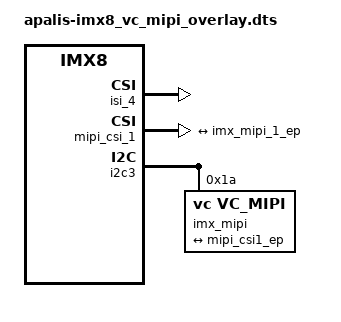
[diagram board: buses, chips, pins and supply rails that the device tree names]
/dts-v1/;
/plugin/;

#include <dt-bindings/clock/imx8-clock.h>
#include <dt-bindings/gpio/gpio.h>

// ------------------------------------------------------------------------------------------------
//  Supported number of lanes
// -----+------------------------------------------------------------------------------------------
//  1   | IMX296
//  2   | OV9281, IMX264, IMX265
//  2,4 | IMX178, IMX183, IMX226, IMX250, IMX252, IMX273, IMX290, IMX327, IMX392, IMX412, IMX415
// -----+------------------------------------------------------------------------------------------
#define VC_MIPI_LANES   2

#if VC_MIPI_LANES == 1
    #define DATA_LANES <1>
    #define NUM_LANES "1" 
#endif
#if VC_MIPI_LANES == 2
    #define DATA_LANES <1 2>
    #define NUM_LANES "2" 
#endif

/ {
	compatible = "toradex,apalis-imx8";
};

&isi_4 { 
	status = "okay";

	cap_device {
		status = "okay";
	};
};

&mipi_csi_1 { 
	#address-cells = <1>;
	#size-cells = <0>;
	// /delete-property/virtual-channel;
	status = "okay";

	port@1 {
		reg = <1>;

		mipi_csi1_ep: endpoint {
			data-lanes = DATA_LANES;
			remote-endpoint = <&imx_mipi_1_ep>;
		};
	};
};

&i2c3 { 
	#address-cells = <1>;
	#size-cells = <0>;
	status = "okay";

	imx_mipi@1a {
		compatible 	= "vc,vc_mipi";
		reg 		= <0x1a>;
		status 		= "okay";
		num_lanes 	= NUM_LANES;

		port {
			imx_mipi_1_ep: endpoint {
				clocks-lanes = <0>;
				remote-endpoint = <&mipi_csi1_ep>;
			};
		};
    	};
};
